# rfc_pha_secure register map
Vendor: Texas Instruments
Peripheral module from a debugger description file (folder CC35X1E).
Registers are 32-bit, access per field, reset 0x0 unless marked. A register's access mark holds for its fields unless they carry their own. Offsets are as the file gives them; lines under a group give offsets from that group; [hi:lo] are bit positions; {n}, {i} and the like mark numbered series; 'fields as' and 'values as' point back to an identical list; <NAME> marks a mode.

## rfc_pha_secure
0x00 phapoly0 rw — LFSR 0 Polynomial Definition
  [31:0] POLY0 — LFSR 0 polynomial taps
0x04 phapoly1 rw — LFSR 1 Polynomial Definition
  [31:0] POLY1 — LFSR 1 polynomial taps
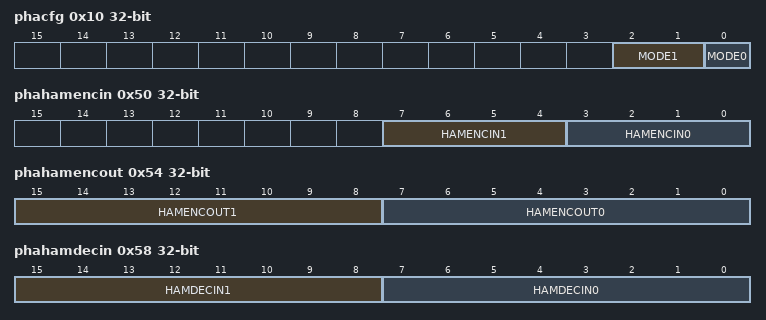
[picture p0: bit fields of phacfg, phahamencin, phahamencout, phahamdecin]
0x10 phacfg — Packet Handler Accelerator Config Register
  [2:1] MODE1 rw — Dual LFSR operating mode
    0=INDEP (LFSR0 and LFSR1 are operated independently); 1=CASC (LFSR0 whitener is followed by LFSR1 CRC); 2=PARAL (LFSR0 and LFSR1 are operated in parallel)
  [0] MODE0 rw — LFSR 0 operating mode
    0=CRC (LFSR 0 is in CRC mode); 1=WHITE (LFSR 0 is in whitening mode)
0x14 phasta ro — Packet Handler Accelerator Status
  [1:0] BUSY — Status busy flags.
    0=IDLE (LFSR n sub-engine idle); 1=BUSY (LFSR n sub-engine busy)
0x20 phalfsr0val rw reset 0xFFFFFFFF — LFSR 0 Current Value
  [31:0] LFSR0VAL — LFSR 0 value
0x24 phalfsr1val rw reset 0xFFFFFFFF — LFSR 1 Current Value
  [31:0] LFSR1VAL — LFSR 1 value
0x30 phalfsr0valbr rw reset 0xFFFFFFFF — LFSR 0 Current Value, Bit-reversed
  [31:0] LFSR0VAL — LFSR 0 value, bit reversed order
0x34 phalfsr1valbr rw reset 0xFFFFFFFF — LFSR 1 Current Value, Bit-reversed
  [31:0] LFSR1VAL — LFSR 1 value, bit reversed order
0x40 phaout0 rw — LFSR 0 Output
  [31:0] OUT0 — Output value of LFSR0
0x48 phaout0br ro — LFSR 0 Output, Bit-reversed
  [31:0] OUT0 — Output value of LFSR0 in bit reversed order
0x50 phahamencin — PHA Hamming Encoder Input
  [7:4] HAMENCIN1 rw — Data to be (8,4,4) extended Hamming encoded. This is a single-error correcting and double-error detecting code.
  [3:0] HAMENCIN0 rw — Data to be (8,4,4) extended Hamming encoded. This is a single-error correcting and double-error detecting code.
0x54 phahamencout ro — PHA Hamming Encoder Output
  [15:8] HAMENCOUT1 — When read, the Hamming encoded value of PHAHAMENCIN.HAMENCIN1 register is returned.
  [7:0] HAMENCOUT0 — When read, the Hamming encoded value of PHAHAMENCIN.HAMENCIN0 register is returned.
0x58 phahamdecin — PHA Hamming Decoder Input
  [15:8] HAMDECIN1 rw — Data to be (8,4,4) extended Hamming decoded.
  [7:0] HAMDECIN0 rw — Data to be (8,4,4) extended Hamming decoded.
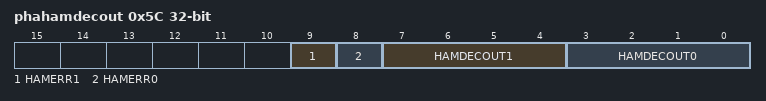
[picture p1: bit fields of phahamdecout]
0x5C phahamdecout ro — PHA Hamming Decoder Output
  [9] HAMERR1 — Uncorrected bit errors was detected when decoding PHAHAMDECIN.HAMDECIN1.
  [8] HAMERR0 — Uncorrected bit errors was detected when decoding PHAHAMDECIN.HAMDECIN0.
  [7:4] HAMDECOUT1 — When read, the decoded value of the PHAHAMDECIN.HAMDECIN1 register is returned.
  [3:0] HAMDECOUT0 — When read, the decoded value of the PHAHAMDECIN.HAMDECIN0 register is returned.
0x100 phalfsr0inl1 — LFSR 0 1-bit Input, LSB First
  [0] LFSR0IN rw — LFSR 0 input value LSB first
{0xFC+4i} phalfsr0inl{i} (i=2..31) — LFSR 0 {i}-bit Input, LSB First
  [{i-1}:0] LFSR0IN rw — LFSR 0 input value LSB first
0x17C phalfsr0inl32 rw — LFSR 0 32-bit Input, LSB First
  [31:0] LFSR0IN — LFSR 0 input value LSB first
0x180 phalfsr0inm1 — LFSR 0 1-bit Input, MSB First
  [0] LFSR0INR rw — LFSR 0 input value MSB first
{0x17C+4i} phalfsr0inm{i} (i=2..31) — LFSR 0 {i}-bit Input, MSB First
  [{i-1}:0] LFSR0INR rw — LFSR 0 input value MSB first
0x1FC phalfsr0inm32 rw — LFSR 0 32-bit Input, MSB First
  [31:0] LFSR0INR — LFSR 0 input value MSB first
0x200 phalfsr1inl1 — LFSR 1 1-bit Input, LSB First
  [0] LFSR1IN rw — LFSR 1 input value LSB first
{0x1FC+4i} phalfsr1inl{i} (i=2..31) — LFSR 1 {i}-bit Input, LSB First
  [{i-1}:0] LFSR1IN rw — LFSR 1 input value LSB first
0x27C phalfsr1inl32 rw — LFSR 1 32-bit Input, LSB First
  [31:0] LFSR1IN — LFSR 1 input value LSB first
0x280 phalfsr1inm1 — LFSR 1 1-bit Input, MSB First
  [0] LFSR1INR rw — LFSR 1 input value MSB first
{0x27C+4i} phalfsr1inm{i} (i=2..31) — LFSR 1 {i}-bit Input, MSB First
  [{i-1}:0] LFSR1INR rw — LFSR 1 input value MSB first
0x2FC phalfsr1inm32 rw — LFSR 1 32-bit Input, MSB First
  [31:0] LFSR1INR — LFSR 1 input value MSB first
